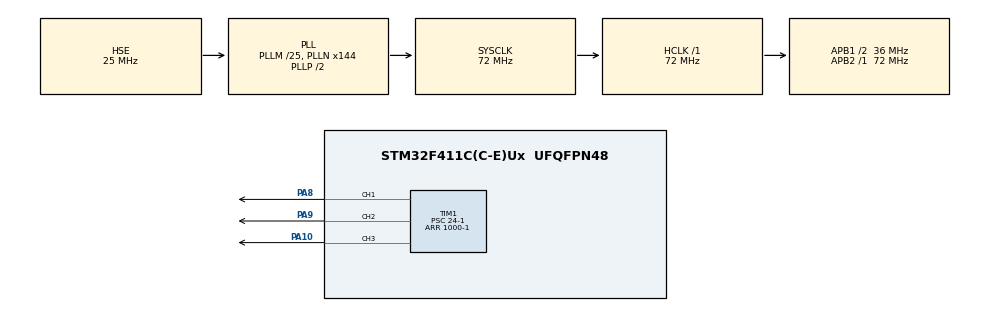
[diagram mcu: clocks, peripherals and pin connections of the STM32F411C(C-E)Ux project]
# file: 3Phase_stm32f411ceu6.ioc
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Dma.Request0=TIM1_UP
Dma.TIM1_UP.0.Direction=DMA_MEMORY_TO_PERIPH
Dma.TIM1_UP.0.FIFOMode=DMA_FIFOMODE_ENABLE
Dma.TIM1_UP.0.FIFOThreshold=DMA_FIFO_THRESHOLD_FULL
Dma.TIM1_UP.0.Instance=DMA2_Stream5
Dma.TIM1_UP.0.MemBurst=DMA_MBURST_INC4
Dma.TIM1_UP.0.MemDataAlignment=DMA_MDATAALIGN_WORD
Dma.TIM1_UP.0.MemInc=DMA_MINC_ENABLE
Dma.TIM1_UP.0.Mode=DMA_CIRCULAR
Dma.TIM1_UP.0.PeriphBurst=DMA_PBURST_SINGLE
Dma.TIM1_UP.0.PeriphDataAlignment=DMA_PDATAALIGN_HALFWORD
Dma.TIM1_UP.0.PeriphInc=DMA_PINC_DISABLE
Dma.TIM1_UP.0.Priority=DMA_PRIORITY_HIGH
Mcu.Family=STM32F4
Mcu.Name=STM32F411C(C-E)Ux
Mcu.Package=UFQFPN48
NVIC.DMA2_Stream5_IRQn=true\:0\:0\:false\:false\:true\:false\:true\:true
NVIC.PriorityGroup=NVIC_PRIORITYGROUP_4
PA10.Signal=S_TIM1_CH3
PA13.Mode=Serial_Wire
PA13.Signal=SYS_JTMS-SWDIO
PA14.Mode=Serial_Wire
PA14.Signal=SYS_JTCK-SWCLK
PA8.Signal=S_TIM1_CH1
PA9.Signal=S_TIM1_CH2
PH0\ -\ OSC_IN.Mode=HSE-External-Oscillator
PH0\ -\ OSC_IN.Signal=RCC_OSC_IN
PH1\ -\ OSC_OUT.Mode=HSE-External-Oscillator
PH1\ -\ OSC_OUT.Signal=RCC_OSC_OUT
ProjectManager.HeapSize=0x200
ProjectManager.StackSize=0x400
ProjectManager.TargetToolchain=STM32CubeIDE
RCC.48MHZClocksFreq_Value=36000000
RCC.AHBFreq_Value=72000000
RCC.APB1CLKDivider=RCC_HCLK_DIV2
RCC.APB1Freq_Value=36000000
RCC.APB1TimFreq_Value=72000000
RCC.APB2Freq_Value=72000000
RCC.APB2TimFreq_Value=72000000
RCC.CortexFreq_Value=72000000
RCC.HCLKFreq_Value=72000000
RCC.HSE_VALUE=25000000
RCC.HSI_VALUE=16000000
RCC.LSE_VALUE=32768
RCC.PLLM=25
RCC.PLLN=144
RCC.PLLSourceVirtual=RCC_PLLSOURCE_HSE
RCC.SYSCLKFreq_VALUE=72000000
RCC.SYSCLKSource=RCC_SYSCLKSOURCE_PLLCLK
RCC.VCOOutputFreq_Value=144000000
SH.S_TIM1_CH1.0=TIM1_CH1,PWM Generation1 CH1
SH.S_TIM1_CH2.0=TIM1_CH2,PWM Generation2 CH2
SH.S_TIM1_CH3.0=TIM1_CH3,PWM Generation3 CH3
STMicroelectronics.X-CUBE-ALGOBUILD.1.3.0.LibraryCcDSPOoLibraryJjDSPOoLibrary=true
TIM1.Channel-PWM\ Generation1\ CH1=TIM_CHANNEL_1
TIM1.Channel-PWM\ Generation2\ CH2=TIM_CHANNEL_2
TIM1.Channel-PWM\ Generation3\ CH3=TIM_CHANNEL_3
TIM1.OCPolarity_1=TIM_OCPOLARITY_LOW
TIM1.OCPolarity_2=TIM_OCPOLARITY_LOW
TIM1.OCPolarity_3=TIM_OCPOLARITY_LOW
TIM1.Period=1000-1
TIM1.Prescaler=24-1
VP_STMicroelectronics.X-CUBE-ALGOBUILD_VS_DSPOoLibraryJjLibrary_1.3.0_1.3.0.Mode=DSPOoLibraryJjLibrary
VP_TIM1_VS_ClockSourceINT.Mode=Internal
board=custom

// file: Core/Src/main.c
/* USER CODE BEGIN Header */
/**
  ******************************************************************************
  * @file           : main.c
  * @brief          : Main program body
  ******************************************************************************
  * @attention
  *
  * Copyright (c) 2024 STMicroelectronics.
  * All rights reserved.
  *
  * This software is licensed under terms that can be found in the LICENSE file
  * in the root directory of this software component.
  * If no LICENSE file comes with this software, it is provided AS-IS.
  *
  ******************************************************************************
  */
/* USER CODE END Header */
#include "main.h"

/* USER CODE BEGIN Includes */
#include "arm_math.h"
/* USER CODE END Includes */

TIM_HandleTypeDef htim1;
DMA_HandleTypeDef hdma_tim1_up;

/* USER CODE BEGIN PV */
volatile uint32_t sindat[180];
uint32_t angle = 0U;
uint8_t freq = 50U;
float32_t uf = 500;
/* USER CODE END PV */

void SystemClock_Config(void);
static void MX_GPIO_Init(void);
static void MX_DMA_Init(void);
static void MX_TIM1_Init(void);

int main(void)
{

  /* MCU Configuration--------------------------------------------------------*/

  /* Reset of all peripherals, Initializes the Flash interface and the Systick. */
  HAL_Init();

  /* Configure the system clock */
  SystemClock_Config();

  /* Initialize all configured peripherals */
  MX_GPIO_Init();
  MX_DMA_Init();
  MX_TIM1_Init();
  /* USER CODE BEGIN 2 */
/*_______________________________ Посчитаем сразу значения скважностей___________________*/
  uf = 500 * ((float32_t)freq / 50);
  //____________________Фаза А_________________________________
for (uint8_t i=0; i<60; i++) {	//Опорная частота ШИМ 3кГц/50Гц получаем 60 точек
     angle = i * 6;				//Начальная фаза
     sindat[3 * i] = uf + uf * (arm_sin_f32((angle * PI)/180));//заполняем массив
/* Реализуем формулу синусоиды A*sin(wt+fi)
 * так как мы не можем сделать отрицательную полуволну, подвинем её вверх на половину амплитуды
 * вся амплитуда это максимальное значение таймера который формирует ШИМ (uf - это половина)
 * функция arm_sin_f32 принимает значения в радианах
 * далее каждый третий элемент массива будет заполнен числом для каждой фазы
*/
    }
  //____________________Фаза В_________________________________
for (uint8_t i=0; i<60; i++) {
     angle = (i * 6) + 120 ;
     sindat[(3 * i) + 1] = uf + uf * (arm_sin_f32((angle * PI)/180));
    }
  //____________________Фаза С_________________________________
for (uint8_t i=0; i<60; i++) {
     angle = (i * 6) + 240;
     sindat[(3 * i) + 2] = uf + uf * (arm_sin_f32((angle * PI)/180));
    }
/* Далее вызовем функцию которая при возникновении заданного события запишет значения из указанного массива
 * sindat в регистры сравнения для трёх каналов ШИМ (CCR1, CCR2, CCR3) первого таймера.
 * в аргументы пишем какой таймер, с какого регистра начинаем, условие срабатывания,указатель на массив,
 * сколько посылок, длинну массива.
 */
HAL_TIM_DMABurst_MultiWriteStart(&htim1, TIM_DMABASE_CCR1, TIM_DMA_UPDATE, (uint32_t*)sindat,
	  	   	   	   	   	   	   	   	   	   	   	   	   	   TIM_DMABURSTLENGTH_3TRANSFERS, 180);
// Далее активируем генерацию ШИМ на трёх каналах
HAL_TIM_PWM_Start(&htim1, TIM_CHANNEL_1);
HAL_TIM_PWM_Start(&htim1, TIM_CHANNEL_2);
HAL_TIM_PWM_Start(&htim1, TIM_CHANNEL_3);

  /* USER CODE END 2 */

  /* Infinite loop */
  while (1)
  {

  }
}

void SystemClock_Config(void)
{
  RCC_OscInitTypeDef RCC_OscInitStruct = {0};
  RCC_ClkInitTypeDef RCC_ClkInitStruct = {0};

  /** Configure the main internal regulator output voltage
  */
  __HAL_RCC_PWR_CLK_ENABLE();
  __HAL_PWR_VOLTAGESCALING_CONFIG(PWR_REGULATOR_VOLTAGE_SCALE1);

  /** Initializes the RCC Oscillators according to the specified parameters
  * in the RCC_OscInitTypeDef structure.
  */
  RCC_OscInitStruct.OscillatorType = RCC_OSCILLATORTYPE_HSE;
  RCC_OscInitStruct.HSEState = RCC_HSE_ON;
  RCC_OscInitStruct.PLL.PLLState = RCC_PLL_ON;
  RCC_OscInitStruct.PLL.PLLSource = RCC_PLLSOURCE_HSE;
  RCC_OscInitStruct.PLL.PLLM = 25;
  RCC_OscInitStruct.PLL.PLLN = 144;
  RCC_OscInitStruct.PLL.PLLP = RCC_PLLP_DIV2;
  RCC_OscInitStruct.PLL.PLLQ = 4;
  if (HAL_RCC_OscConfig(&RCC_OscInitStruct) != HAL_OK)
  {
    Error_Handler();
  }

  /** Initializes the CPU, AHB and APB buses clocks
  */
  RCC_ClkInitStruct.ClockType = RCC_CLOCKTYPE_HCLK|RCC_CLOCKTYPE_SYSCLK
                              |RCC_CLOCKTYPE_PCLK1|RCC_CLOCKTYPE_PCLK2;
  RCC_ClkInitStruct.SYSCLKSource = RCC_SYSCLKSOURCE_PLLCLK;
  RCC_ClkInitStruct.AHBCLKDivider = RCC_SYSCLK_DIV1;
  RCC_ClkInitStruct.APB1CLKDivider = RCC_HCLK_DIV2;
  RCC_ClkInitStruct.APB2CLKDivider = RCC_HCLK_DIV1;

  if (HAL_RCC_ClockConfig(&RCC_ClkInitStruct, FLASH_LATENCY_2) != HAL_OK)
  {
    Error_Handler();
  }
}

static void MX_TIM1_Init(void)
{

  TIM_ClockConfigTypeDef sClockSourceConfig = {0};
  TIM_MasterConfigTypeDef sMasterConfig = {0};
  TIM_OC_InitTypeDef sConfigOC = {0};
  TIM_BreakDeadTimeConfigTypeDef sBreakDeadTimeConfig = {0};

  htim1.Instance = TIM1;
  htim1.Init.Prescaler = 24-1;
  htim1.Init.CounterMode = TIM_COUNTERMODE_UP;
  htim1.Init.Period = 1000-1;
  htim1.Init.ClockDivision = TIM_CLOCKDIVISION_DIV1;
  htim1.Init.RepetitionCounter = 0;
  htim1.Init.AutoReloadPreload = TIM_AUTORELOAD_PRELOAD_DISABLE;
  if (HAL_TIM_Base_Init(&htim1) != HAL_OK)
  {
    Error_Handler();
  }
  sClockSourceConfig.ClockSource = TIM_CLOCKSOURCE_INTERNAL;
  if (HAL_TIM_ConfigClockSource(&htim1, &sClockSourceConfig) != HAL_OK)
  {
    Error_Handler();
  }
  if (HAL_TIM_PWM_Init(&htim1) != HAL_OK)
  {
    Error_Handler();
  }
  sMasterConfig.MasterOutputTrigger = TIM_TRGO_RESET;
  sMasterConfig.MasterSlaveMode = TIM_MASTERSLAVEMODE_DISABLE;
  if (HAL_TIMEx_MasterConfigSynchronization(&htim1, &sMasterConfig) != HAL_OK)
  {
    Error_Handler();
  }
  sConfigOC.OCMode = TIM_OCMODE_PWM1;
  sConfigOC.Pulse = 0;
  sConfigOC.OCPolarity = TIM_OCPOLARITY_LOW;
  sConfigOC.OCNPolarity = TIM_OCNPOLARITY_HIGH;
  sConfigOC.OCFastMode = TIM_OCFAST_DISABLE;
  sConfigOC.OCIdleState = TIM_OCIDLESTATE_RESET;
  sConfigOC.OCNIdleState = TIM_OCNIDLESTATE_RESET;
  if (HAL_TIM_PWM_ConfigChannel(&htim1, &sConfigOC, TIM_CHANNEL_1) != HAL_OK)
  {
    Error_Handler();
  }
  if (HAL_TIM_PWM_ConfigChannel(&htim1, &sConfigOC, TIM_CHANNEL_2) != HAL_OK)
  {
    Error_Handler();
  }
  if (HAL_TIM_PWM_ConfigChannel(&htim1, &sConfigOC, TIM_CHANNEL_3) != HAL_OK)
  {
    Error_Handler();
  }
  sBreakDeadTimeConfig.OffStateRunMode = TIM_OSSR_DISABLE;
  sBreakDeadTimeConfig.OffStateIDLEMode = TIM_OSSI_DISABLE;
  sBreakDeadTimeConfig.LockLevel = TIM_LOCKLEVEL_OFF;
  sBreakDeadTimeConfig.DeadTime = 0;
  sBreakDeadTimeConfig.BreakState = TIM_BREAK_DISABLE;
  sBreakDeadTimeConfig.BreakPolarity = TIM_BREAKPOLARITY_HIGH;
  sBreakDeadTimeConfig.AutomaticOutput = TIM_AUTOMATICOUTPUT_DISABLE;
  if (HAL_TIMEx_ConfigBreakDeadTime(&htim1, &sBreakDeadTimeConfig) != HAL_OK)
  {
    Error_Handler();
  }
  HAL_TIM_MspPostInit(&htim1);

}

static void MX_DMA_Init(void)
{

  /* DMA controller clock enable */
  __HAL_RCC_DMA2_CLK_ENABLE();

  /* DMA interrupt init */
  /* DMA2_Stream5_IRQn interrupt configuration */
  HAL_NVIC_SetPriority(DMA2_Stream5_IRQn, 0, 0);
  HAL_NVIC_EnableIRQ(DMA2_Stream5_IRQn);

}

static void MX_GPIO_Init(void)
{

  /* GPIO Ports Clock Enable */
  __HAL_RCC_GPIOH_CLK_ENABLE();
  __HAL_RCC_GPIOA_CLK_ENABLE();

}

void Error_Handler(void)
{
  __disable_irq();
  while (1)
  {
  }
}
